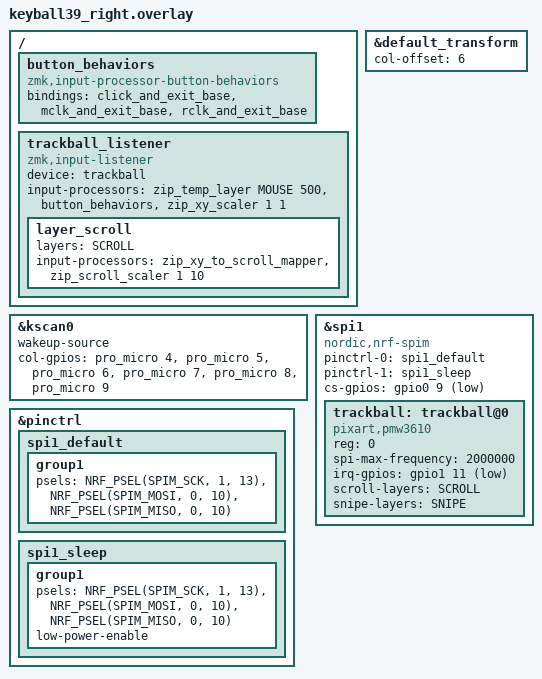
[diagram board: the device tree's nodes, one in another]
/*
 * Copyright (c) 2020 ZMK Contributors
 *
 * SPDX-License-Identifier: MIT
 */
 
#include "keyball39.dtsi"
#include <input/processors.dtsi>
#define MOUSE   6
#define SCROLL  7
#define SNIPE   8

&default_transform {
    col-offset = <6>;
};

&kscan0 {
	wakeup-source;
	col-gpios
		= <&pro_micro 4 GPIO_ACTIVE_HIGH>
		, <&pro_micro 5 GPIO_ACTIVE_HIGH>
		, <&pro_micro 6 GPIO_ACTIVE_HIGH>
		, <&pro_micro 7 GPIO_ACTIVE_HIGH>
		, <&pro_micro 8 GPIO_ACTIVE_HIGH>
        , <&pro_micro 9 GPIO_ACTIVE_HIGH>
		;
};

&pinctrl {
    spi1_default: spi1_default {
        group1 {
            psels = <NRF_PSEL(SPIM_SCK, 1, 13)>,
                <NRF_PSEL(SPIM_MOSI, 0, 10)>,
                <NRF_PSEL(SPIM_MISO, 0, 10)>;
        };
    };

    spi1_sleep: spi1_sleep {
        group1 {
            psels = <NRF_PSEL(SPIM_SCK, 1, 13)>,
                <NRF_PSEL(SPIM_MOSI, 0, 10)>,
                <NRF_PSEL(SPIM_MISO, 0, 10)>;
            low-power-enable;
        };
    };
};

&spi1 {
    status = "okay";
    compatible = "nordic,nrf-spim";
    pinctrl-0 = <&spi1_default>;
    pinctrl-1 = <&spi1_sleep>;
    pinctrl-names = "default", "sleep";
    cs-gpios = <&gpio0 9 GPIO_ACTIVE_LOW>;

    trackball: trackball@0 {
        status = "okay";
        compatible = "pixart,pmw3610";
        reg = <0>;
        spi-max-frequency = <2000000>;
        irq-gpios = <&gpio1 11 (GPIO_ACTIVE_LOW | GPIO_PULL_UP)>;
//        automouse-layer = <4>;
	scroll-layers = <SCROLL>;
	snipe-layers = <SNIPE>;
    };
};

/ {
  /* Define button behaviors processor */
  button_behaviors: button_behaviors {
    compatible = "zmk,input-processor-button-behaviors";
    #input-processor-cells = <0>;
    /* Order is Left, Middle, Right */
    bindings = <&click_and_exit_base &mclk_and_exit_base &rclk_and_exit_base>;
  };

  trackball_listener {
    compatible = "zmk,input-listener";
    device = <&trackball>;
    /* Auto-enable the MOUSE layer on movement; exit after 500ms idle */
    input-processors = <
        &zip_temp_layer MOUSE 500
        &button_behaviors
        &zip_xy_scaler 1 1
    >;

    /* While on SCROLL layer, convert XY to scroll and slow it down */
    layer_scroll {
      layers = <SCROLL>;
      input-processors = <
        &zip_xy_to_scroll_mapper
        &zip_scroll_scaler 1 10
      >;
    };
  };
};
